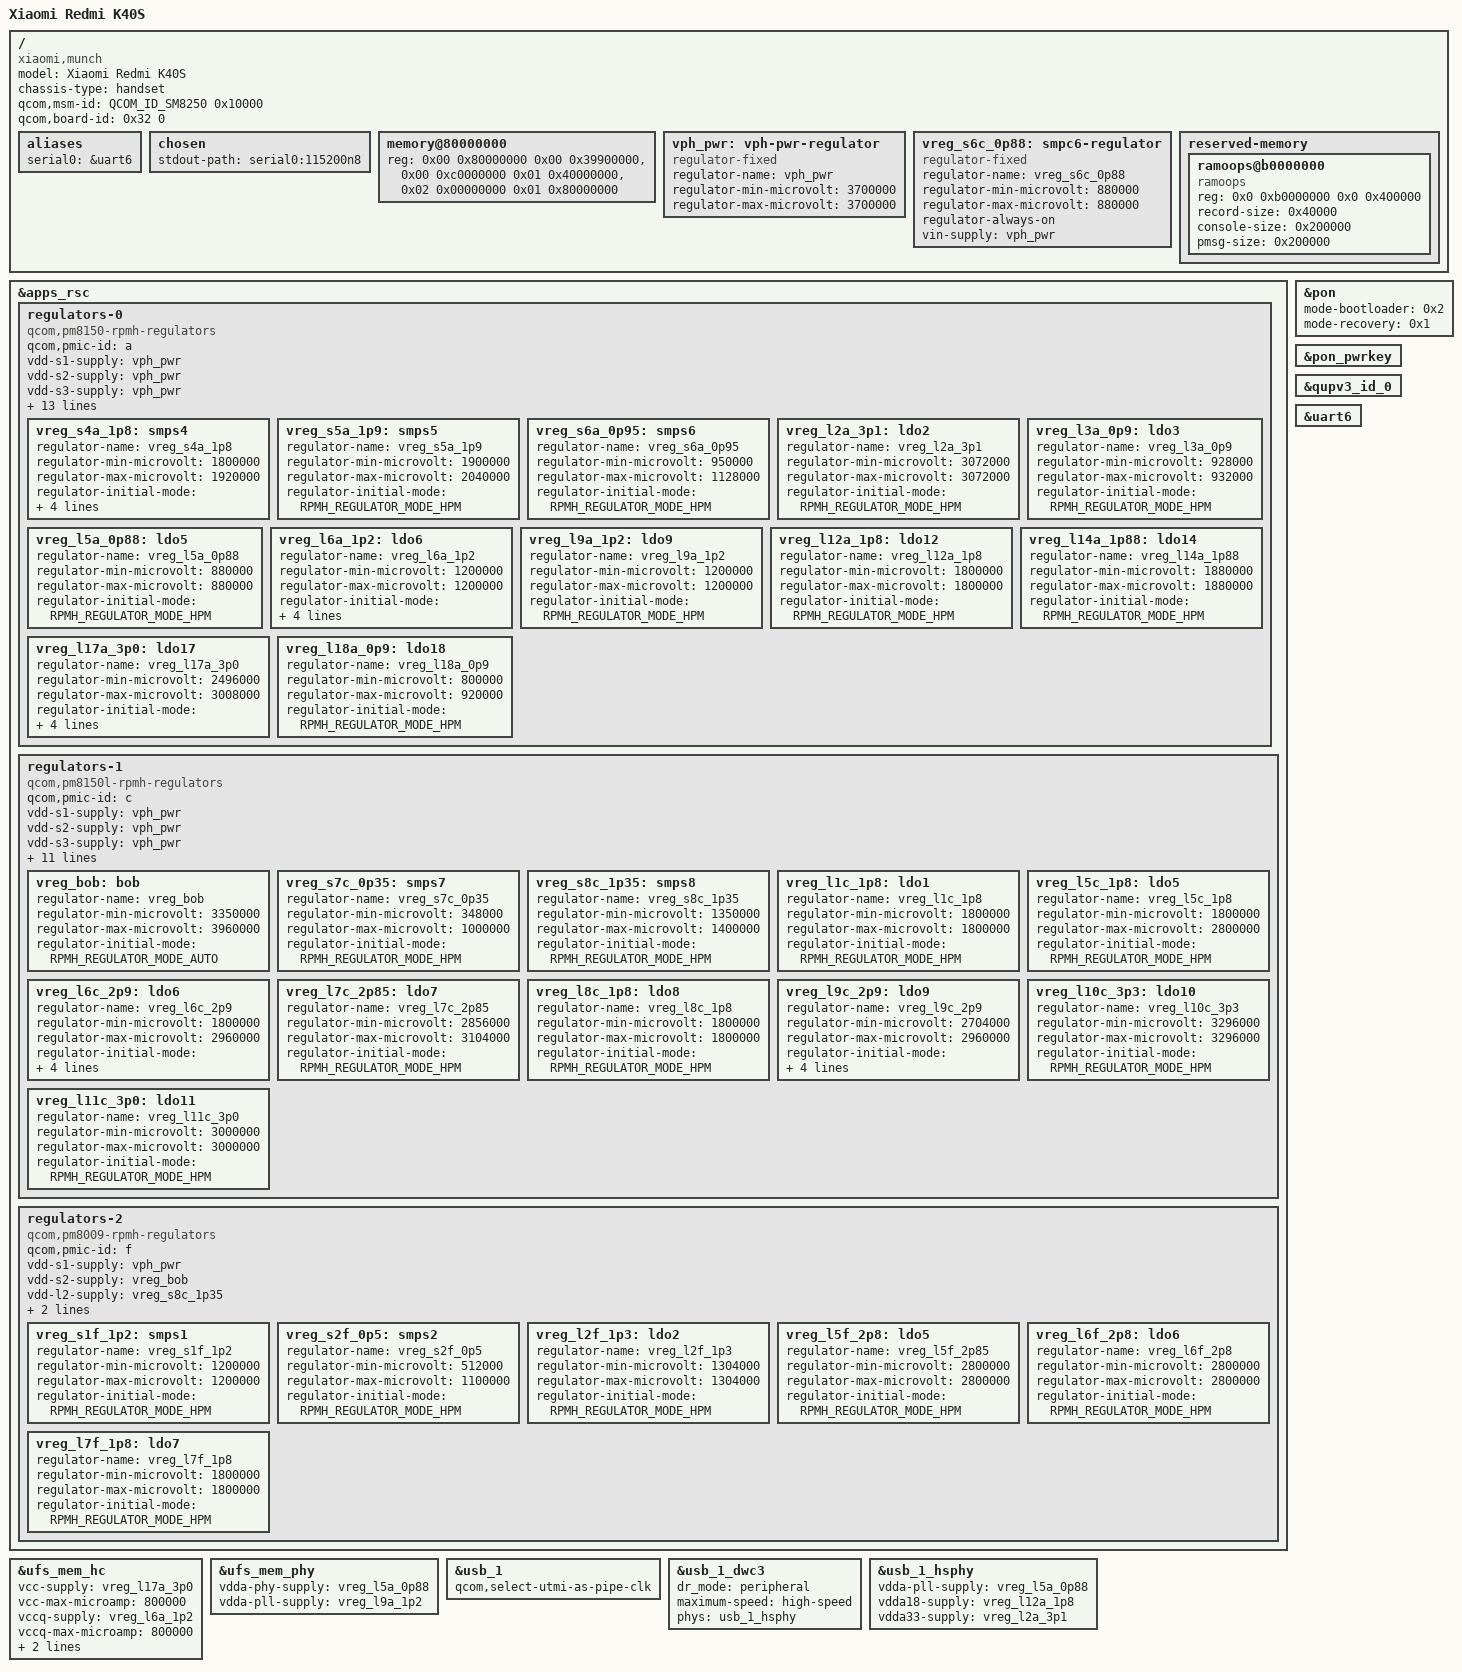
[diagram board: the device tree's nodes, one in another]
// SPDX-License-Identifier: GPL-2.0-only OR BSD-2-Clause
/*
 * Xiaomi Redmi K40S (munch / SM8250) 最小设备树
 *
 * 只覆盖「内核能不能起来、起不来时能不能留下日志」所需的最小节点：
 * 内存、PMIC 稳压器、UFS、USB 2.0、ramoops、调试串口。
 * 屏幕（l11r）、触摸（ft3658u）、WiFi（QCA6391）、音频、摄像头都不在这里。
 *
 * 骨架来自 sm8250-xiaomi-elish-common.dtsi / sm8250-xiaomi-pipa.dts；
 * UFS/USB 的稳压器对应关系用 vendor 树 xiaomi-sm8250-common.dtsi、
 * kona-usb.dtsi 核对过，与 munch 实际一致。
 */

/dts-v1/;

#include <dt-bindings/arm/qcom,ids.h>
#include <dt-bindings/regulator/qcom,rpmh-regulator.h>
#include "sm8250.dtsi"
#include "pm8150.dtsi"
#include "pm8150b.dtsi"
#include "pm8150l.dtsi"
#include "pm8009.dtsi"

/ {
	model = "Xiaomi Redmi K40S";
	compatible = "xiaomi,munch", "qcom,sm8250";
	chassis-type = "handset";

	/* bootloader 靠这两个值挑设备树：msm-id 来自 vendor kona.dtsi，board-id 来自 munch overlay */
	qcom,msm-id = <QCOM_ID_SM8250 0x10000>;
	qcom,board-id = <0x32 0>;

	aliases {
		serial0 = &uart6;
	};

	chosen {
		#address-cells = <2>;
		#size-cells = <2>;
		ranges;
		/*
		 * bootargs 故意留空：由 ABL 注入。
		 * stdout-path 是没给 console= 时的兜底，保证 ttyMSM0 注册成控制台，
		 * 这样 pstore console 才收得到内核日志。
		 */
		stdout-path = "serial0:115200n8";
	};

	memory@80000000 {
		device_type = "memory";
		/*
		 * 12 GB 变体，三段非连续，0xB9900000-0xC0000000 为硬件空洞。
		 * 依据设备实读：/proc/device-tree/memory/reg 与 /proc/iomem
		 * （iomem 里 0xb9900000-0xbfffffff 不在任何 System RAM 段内）：
		 *   0x80000000 - 0xb9900000   921.6 MB
		 *   0xc0000000 - 0x200000000    5 GB
		 *   0x200000000 - 0x380000000   6 GB
		 * 空洞绝不能合并进 memory，否则内核会在不存在的地址上分配页表/slab，
		 * 盲启动直接挂死，而且挂死时 pstore 可能还没初始化。
		 *
		 * 第二段 size 写成 <0x01 0x40000000>（高低位，= 5 GB）而不是单个
		 * <0x140000000>：reg 每个单元格是 32 位，写超了 dtc 会静默截断成 1 GB。
		 */
		reg = <0x00 0x80000000 0x00 0x39900000>,
		      <0x00 0xc0000000 0x01 0x40000000>,
		      <0x02 0x00000000 0x01 0x80000000>;
	};

	vph_pwr: vph-pwr-regulator {
		compatible = "regulator-fixed";
		regulator-name = "vph_pwr";
		regulator-min-microvolt = <3700000>;
		regulator-max-microvolt = <3700000>;
	};

	/* S6c 其实是 ebi.lvl，只为补齐 LDO 的 supply 依赖 */
	vreg_s6c_0p88: smpc6-regulator {
		compatible = "regulator-fixed";
		regulator-name = "vreg_s6c_0p88";
		regulator-min-microvolt = <880000>;
		regulator-max-microvolt = <880000>;
		regulator-always-on;
		vin-supply = <&vph_pwr>;
	};

	/*
	 * 只新增 ramoops，sm8250.dtsi 里已有的 reserved-memory 节点（hyp / xbl_aop /
	 * cmd_db / smem / removed / camera / wlan / ipa / gpu / npu / video / cvp /
	 * cdsp / slpi / adsp / spss / cdsp_secure_heap / adsp_rpc_remote_heap）一个都没删——
	 * 那些是固件真正占用的内存，删了内核会踩进去。
	 */
	reserved-memory {
		/*
		 * 地址/大小按 Lead 实机核对结果：ramoops 到 0xb0400000 为止，
		 * 后面 0xb0400000 起是 Android 的 disp_rdump_region，不重叠。
		 * 注意：console 0x200000 + pmsg 0x200000 正好占满 4 MB，
		 * 驱动算出的 dmesg 区大小是 0，所以 record-size 实际不生效
		 * （不影响 console-ramoops / pmsg-ramoops 这两条通道）。
		 */
		ramoops@b0000000 {
			compatible = "ramoops";
			reg = <0x0 0xb0000000 0x0 0x400000>;
			record-size = <0x40000>;
			console-size = <0x200000>;
			pmsg-size = <0x200000>;
		};
	};
};

&apps_rsc {
	regulators-0 {
		compatible = "qcom,pm8150-rpmh-regulators";
		qcom,pmic-id = "a";

		vdd-s1-supply = <&vph_pwr>;
		vdd-s2-supply = <&vph_pwr>;
		vdd-s3-supply = <&vph_pwr>;
		vdd-s4-supply = <&vph_pwr>;
		vdd-s5-supply = <&vph_pwr>;
		vdd-s6-supply = <&vph_pwr>;
		vdd-s7-supply = <&vph_pwr>;
		vdd-s8-supply = <&vph_pwr>;
		vdd-s9-supply = <&vph_pwr>;
		vdd-s10-supply = <&vph_pwr>;
		vdd-l1-l8-l11-supply = <&vreg_s6c_0p88>;
		vdd-l2-l10-supply = <&vreg_bob>;
		vdd-l3-l4-l5-l18-supply = <&vreg_s6a_0p95>;
		vdd-l6-l9-supply = <&vreg_s8c_1p35>;
		vdd-l7-l12-l14-l15-supply = <&vreg_s5a_1p9>;
		vdd-l13-l16-l17-supply = <&vreg_bob>;

		/* (S1+S2+S3) - cx.lvl (ARC) */

		vreg_s4a_1p8: smps4 {
			regulator-name = "vreg_s4a_1p8";
			regulator-min-microvolt = <1800000>;
			regulator-max-microvolt = <1920000>;
			regulator-initial-mode = <RPMH_REGULATOR_MODE_HPM>;
			regulator-allow-set-load;
			regulator-allowed-modes = <RPMH_REGULATOR_MODE_LPM
						   RPMH_REGULATOR_MODE_HPM>;
		};

		vreg_s5a_1p9: smps5 {
			regulator-name = "vreg_s5a_1p9";
			regulator-min-microvolt = <1900000>;
			regulator-max-microvolt = <2040000>;
			regulator-initial-mode = <RPMH_REGULATOR_MODE_HPM>;
		};

		vreg_s6a_0p95: smps6 {
			regulator-name = "vreg_s6a_0p95";
			regulator-min-microvolt = <950000>;
			regulator-max-microvolt = <1128000>;
			regulator-initial-mode = <RPMH_REGULATOR_MODE_HPM>;
		};

		vreg_l2a_3p1: ldo2 {
			regulator-name = "vreg_l2a_3p1";
			regulator-min-microvolt = <3072000>;
			regulator-max-microvolt = <3072000>;
			regulator-initial-mode = <RPMH_REGULATOR_MODE_HPM>;
		};

		vreg_l3a_0p9: ldo3 {
			regulator-name = "vreg_l3a_0p9";
			regulator-min-microvolt = <928000>;
			regulator-max-microvolt = <932000>;
			regulator-initial-mode = <RPMH_REGULATOR_MODE_HPM>;
		};

		/* L4 - lmx.lvl (ARC) */

		vreg_l5a_0p88: ldo5 {
			regulator-name = "vreg_l5a_0p88";
			regulator-min-microvolt = <880000>;
			regulator-max-microvolt = <880000>;
			regulator-initial-mode = <RPMH_REGULATOR_MODE_HPM>;
		};

		vreg_l6a_1p2: ldo6 {
			regulator-name = "vreg_l6a_1p2";
			regulator-min-microvolt = <1200000>;
			regulator-max-microvolt = <1200000>;
			regulator-initial-mode = <RPMH_REGULATOR_MODE_HPM>;
			regulator-allow-set-load;
			regulator-allowed-modes = <RPMH_REGULATOR_MODE_LPM
						   RPMH_REGULATOR_MODE_HPM>;
		};

		/* L7 is unused. */

		vreg_l9a_1p2: ldo9 {
			regulator-name = "vreg_l9a_1p2";
			regulator-min-microvolt = <1200000>;
			regulator-max-microvolt = <1200000>;
			regulator-initial-mode = <RPMH_REGULATOR_MODE_HPM>;
		};

		/* L10 is unused, L11 - lcx.lvl (ARC) */

		vreg_l12a_1p8: ldo12 {
			regulator-name = "vreg_l12a_1p8";
			regulator-min-microvolt = <1800000>;
			regulator-max-microvolt = <1800000>;
			regulator-initial-mode = <RPMH_REGULATOR_MODE_HPM>;
		};

		/* L13 is unused. */

		vreg_l14a_1p88: ldo14 {
			regulator-name = "vreg_l14a_1p88";
			regulator-min-microvolt = <1880000>;
			regulator-max-microvolt = <1880000>;
			regulator-initial-mode = <RPMH_REGULATOR_MODE_HPM>;
		};

		/* L15 & L16 are unused. */

		vreg_l17a_3p0: ldo17 {
			regulator-name = "vreg_l17a_3p0";
			regulator-min-microvolt = <2496000>;
			regulator-max-microvolt = <3008000>;
			regulator-initial-mode = <RPMH_REGULATOR_MODE_HPM>;
			regulator-allow-set-load;
			regulator-allowed-modes = <RPMH_REGULATOR_MODE_LPM
						   RPMH_REGULATOR_MODE_HPM>;
		};

		vreg_l18a_0p9: ldo18 {
			regulator-name = "vreg_l18a_0p9";
			regulator-min-microvolt = <800000>;
			regulator-max-microvolt = <920000>;
			regulator-initial-mode = <RPMH_REGULATOR_MODE_HPM>;
		};
	};

	/*
	 * Remaining regulators that are not yet supported:
	 * OLEDB: 4925000-8100000
	 * ab: 4600000-6100000
	 * ibb: 800000-5400000
	 */
	regulators-1 {
		compatible = "qcom,pm8150l-rpmh-regulators";
		qcom,pmic-id = "c";

		vdd-s1-supply = <&vph_pwr>;
		vdd-s2-supply = <&vph_pwr>;
		vdd-s3-supply = <&vph_pwr>;
		vdd-s4-supply = <&vph_pwr>;
		vdd-s5-supply = <&vph_pwr>;
		vdd-s6-supply = <&vph_pwr>;
		vdd-s7-supply = <&vph_pwr>;
		vdd-s8-supply = <&vph_pwr>;
		vdd-l1-l8-supply = <&vreg_s4a_1p8>;
		vdd-l2-l3-supply = <&vreg_s8c_1p35>;
		vdd-l4-l5-l6-supply = <&vreg_bob>;
		vdd-l7-l11-supply = <&vreg_bob>;
		vdd-l9-l10-supply = <&vreg_bob>;
		vdd-bob-supply = <&vph_pwr>;

		vreg_bob: bob {
			regulator-name = "vreg_bob";
			regulator-min-microvolt = <3350000>;
			regulator-max-microvolt = <3960000>;
			regulator-initial-mode = <RPMH_REGULATOR_MODE_AUTO>;
		};

		/*
		 * S1-S6 are ARCs:
		 * (S1+S2) - gfx.lvl,
		 * S3 - mx.lvl,
		 * (S4+S5) - mmcx.lvl,
		 * S6 - ebi.lvl
		 */

		vreg_s7c_0p35: smps7 {
			regulator-name = "vreg_s7c_0p35";
			regulator-min-microvolt = <348000>;
			regulator-max-microvolt = <1000000>;
			regulator-initial-mode = <RPMH_REGULATOR_MODE_HPM>;
		};

		vreg_s8c_1p35: smps8 {
			regulator-name = "vreg_s8c_1p35";
			regulator-min-microvolt = <1350000>;
			regulator-max-microvolt = <1400000>;
			regulator-initial-mode = <RPMH_REGULATOR_MODE_HPM>;
		};

		vreg_l1c_1p8: ldo1 {
			regulator-name = "vreg_l1c_1p8";
			regulator-min-microvolt = <1800000>;
			regulator-max-microvolt = <1800000>;
			regulator-initial-mode = <RPMH_REGULATOR_MODE_HPM>;
		};

		/* L2-4 are unused. */

		vreg_l5c_1p8: ldo5 {
			regulator-name = "vreg_l5c_1p8";
			regulator-min-microvolt = <1800000>;
			regulator-max-microvolt = <2800000>;
			regulator-initial-mode = <RPMH_REGULATOR_MODE_HPM>;
		};

		vreg_l6c_2p9: ldo6 {
			regulator-name = "vreg_l6c_2p9";
			regulator-min-microvolt = <1800000>;
			regulator-max-microvolt = <2960000>;
			regulator-initial-mode = <RPMH_REGULATOR_MODE_HPM>;
			regulator-allow-set-load;
			regulator-allowed-modes = <RPMH_REGULATOR_MODE_LPM
						   RPMH_REGULATOR_MODE_HPM>;
		};

		vreg_l7c_2p85: ldo7 {
			regulator-name = "vreg_l7c_2p85";
			regulator-min-microvolt = <2856000>;
			regulator-max-microvolt = <3104000>;
			regulator-initial-mode = <RPMH_REGULATOR_MODE_HPM>;
		};

		vreg_l8c_1p8: ldo8 {
			regulator-name = "vreg_l8c_1p8";
			regulator-min-microvolt = <1800000>;
			regulator-max-microvolt = <1800000>;
			regulator-initial-mode = <RPMH_REGULATOR_MODE_HPM>;
		};

		vreg_l9c_2p9: ldo9 {
			regulator-name = "vreg_l9c_2p9";
			regulator-min-microvolt = <2704000>;
			regulator-max-microvolt = <2960000>;
			regulator-initial-mode = <RPMH_REGULATOR_MODE_HPM>;
			regulator-allow-set-load;
			regulator-allowed-modes = <RPMH_REGULATOR_MODE_LPM
						   RPMH_REGULATOR_MODE_HPM>;
		};

		vreg_l10c_3p3: ldo10 {
			regulator-name = "vreg_l10c_3p3";
			regulator-min-microvolt = <3296000>;
			regulator-max-microvolt = <3296000>;
			regulator-initial-mode = <RPMH_REGULATOR_MODE_HPM>;
		};

		vreg_l11c_3p0: ldo11 {
			regulator-name = "vreg_l11c_3p0";
			regulator-min-microvolt = <3000000>;
			regulator-max-microvolt = <3000000>;
			regulator-initial-mode = <RPMH_REGULATOR_MODE_HPM>;
		};
	};

	regulators-2 {
		compatible = "qcom,pm8009-rpmh-regulators";
		qcom,pmic-id = "f";

		vdd-s1-supply = <&vph_pwr>;
		vdd-s2-supply = <&vreg_bob>;
		vdd-l2-supply = <&vreg_s8c_1p35>;
		vdd-l5-l6-supply = <&vreg_bob>;
		vdd-l7-supply = <&vreg_s4a_1p8>;

		vreg_s1f_1p2: smps1 {
			regulator-name = "vreg_s1f_1p2";
			regulator-min-microvolt = <1200000>;
			regulator-max-microvolt = <1200000>;
			regulator-initial-mode = <RPMH_REGULATOR_MODE_HPM>;
		};

		vreg_s2f_0p5: smps2 {
			regulator-name = "vreg_s2f_0p5";
			regulator-min-microvolt = <512000>;
			regulator-max-microvolt = <1100000>;
			regulator-initial-mode = <RPMH_REGULATOR_MODE_HPM>;
		};

		/* L1 is unused. */

		vreg_l2f_1p3: ldo2 {
			regulator-name = "vreg_l2f_1p3";
			regulator-min-microvolt = <1304000>;
			regulator-max-microvolt = <1304000>;
			regulator-initial-mode = <RPMH_REGULATOR_MODE_HPM>;
		};

		/* L3 & L4 are unused. */

		vreg_l5f_2p8: ldo5 {
			regulator-name = "vreg_l5f_2p85";
			regulator-min-microvolt = <2800000>;
			regulator-max-microvolt = <2800000>;
			regulator-initial-mode = <RPMH_REGULATOR_MODE_HPM>;
		};

		vreg_l6f_2p8: ldo6 {
			regulator-name = "vreg_l6f_2p8";
			regulator-min-microvolt = <2800000>;
			regulator-max-microvolt = <2800000>;
			regulator-initial-mode = <RPMH_REGULATOR_MODE_HPM>;
		};

		vreg_l7f_1p8: ldo7 {
			regulator-name = "vreg_l7f_1p8";
			regulator-min-microvolt = <1800000>;
			regulator-max-microvolt = <1800000>;
			regulator-initial-mode = <RPMH_REGULATOR_MODE_HPM>;
		};
	};
};

&pon {
	mode-bootloader = <0x2>;
	mode-recovery = <0x1>;
};

&pon_pwrkey {
	status = "okay";
};

&qupv3_id_0 {
	status = "okay";
};

/* SE6 四线 UART：vendor 树里 munch 打开的就是 qupv3_se6_4uart */
&uart6 {
	status = "okay";
};

&ufs_mem_hc {
	vcc-supply = <&vreg_l17a_3p0>;
	vcc-max-microamp = <800000>;
	vccq-supply = <&vreg_l6a_1p2>;
	vccq-max-microamp = <800000>;
	vccq2-supply = <&vreg_s4a_1p8>;
	vccq2-max-microamp = <800000>;
	status = "okay";
};

&ufs_mem_phy {
	vdda-phy-supply = <&vreg_l5a_0p88>;
	vdda-pll-supply = <&vreg_l9a_1p2>;
	status = "okay";
};

/*
 * munch 只有 USB 2.0（vendor 树里 dwc3 用 usb2_phy0 + usb_nop_phy），
 * 所以丢掉 USB3/DP PHY，只用 HS PHY。
 */
&usb_1 {
	qcom,select-utmi-as-pipe-clk;
	status = "okay";
};

&usb_1_dwc3 {
	dr_mode = "peripheral";
	maximum-speed = "high-speed";
	phys = <&usb_1_hsphy>;
	phy-names = "usb2-phy";
};

&usb_1_hsphy {
	vdda-pll-supply = <&vreg_l5a_0p88>;
	vdda18-supply = <&vreg_l12a_1p8>;
	vdda33-supply = <&vreg_l2a_3p1>;
	status = "okay";
};
